# R7FA8D1BH register map
Vendor: Renesas; Series: RA8; File version: 1.2
CPU: CM85 r0p0, little endian, MPU, FPU, VTOR, 4 interrupt priority bits
Registers are 32-bit, read-write, reset 0x0 unless marked. A register's access mark holds for its fields unless they carry their own. Offsets are from the block's base; [hi:lo] are bit positions; 'fields as' and 'values as' point back to an identical list.

## SSIE0 — Serial Sound Interface Enhanced (SSIE)
Base 0x4025D000
Same registers: SSIE1 0x4025D100, SSIE0_NS 0x5025D000, SSIE1_NS 0x5025D100
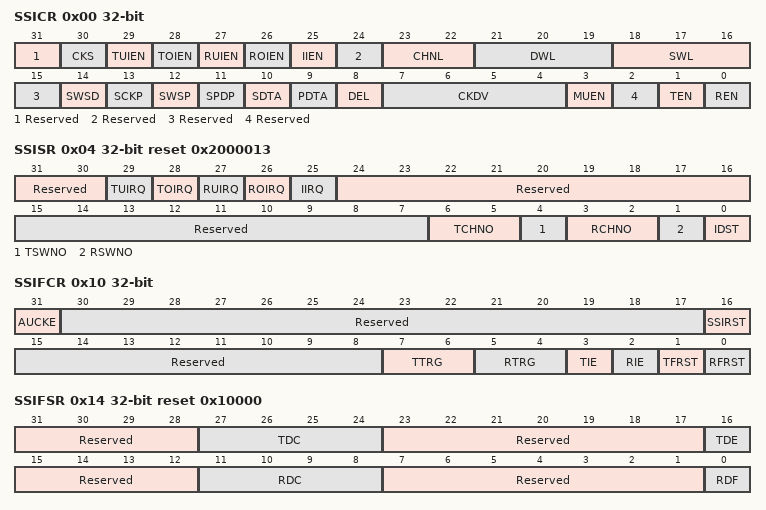
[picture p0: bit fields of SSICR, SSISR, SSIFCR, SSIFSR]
0x00 SSICR — Control Register
  [31] Reserved — This bit is read as 0. The write value should be 0.
  [30] CKS — Oversampling Clock Select
    0=AUDIO_CLK input; 1=Setting prohibited
  [29] TUIEN — Transmit Underflow Interrupt Enable
    0=Disables an underflow interrupt; 1=Enables an underflow interrupt
  [28] TOIEN — Transmit Overflow Interrupt Enable
    0=Disables an overflow interrupt; 1=Enables an overflow interrupt
  [27] RUIEN — Receive Underflow Interrupt Enable
    values as TUIEN
  [26] ROIEN — Receive Overflow Interrupt Enable
    values as TOIEN
  [25] IIEN — Idle Mode Interrupt Enable
    0=Disables an idle mode interrupt; 1=Enables an idle mode interrupt
  [24] Reserved — This bit is read as 0. The write value should be 0.
  [23:22] CHNL — Channels
    0=One channel; other=others (Settings other than above are prohibited.)
  [21:19] DWL — Data Word Length
    0=8 bits; 1=16 bits; 2=18 bits; 3=20 bits; 4=22 bits; 5=24 bits; other=others (Settings other than above are prohibited.)
  [18:16] SWL — System Word LengthSet the system word length to the bit clock frequency/2 fs.
    0=8 bits (serial bit clock frequency = 16fs ); 1=16 bits (serial bit clock frequency = 32fs ); 2=24 bits (serial bit clock frequency = 48fs ); 3=32 bits (serial bit clock frequency = 64fs ); other=others (Settings other than above are prohibited.)
  [15] Reserved — This bit is read as 0. The write value should be 0.
  [14] SWSD — Serial WS Direction NOTE: Only the following settings are allowed: (SCKD, SWSD) = (0, 0) and (1, 1). Other settings are prohibited.
    0=Serial word select is input, slave mode; 1=Serial word select is output, master mode
  [13] SCKP — Serial Bit Clock Polarity
    0=SSIWS and SSIDATA change at the SSISCK falling edge (sampled at the SCK rising edge); 1=SSIWS and SSIDATA change at the SSISCK rising edge (sampled at the SCK falling edge)
  [12] SWSP — Serial WS Polarity
    0=SSIWS is low for 1st channel, high for 2nd channel; 1=SSIWS is high for 1st channel, low for 2nd channel
  [11] SPDP — Serial Padding Polarity
    0=Padding bits are low; 1=Padding bits are high
  [10] SDTA — Serial Data Alignment
    0=Transmitting and receiving in the order of serial data and padding bits; 1=Transmitting and receiving in the order of padding bits and serial data
  [9] PDTA — Parallel Data Alignment
    0=The lower bits of parallel data (SSITDR, SSIRDR) are transferred prior to the upper bits.(When data word length is 8 or 16 bits) / Parallel data (SSITDR, SSIRDR) is left-aligned.(When data word length is 18, 20, 22, or 24 bits); 1=The upper bits of parallel data (SSITDR, SSIRDR) are transferred prior to the lower bits.(When data word length is 8 or 16 bits) / Parallel data (SSITDR, SSIRDR) is right-aligned.(When data word length is 18, 20, 22, or 24 bits)
  [8] DEL — Serial Data Delay
    0=1 clock cycle delay between SSIWS and SSIDATA; 1=No delay between SSIWS and SSIDATA
  [7:4] CKDV — Serial Oversampling Clock Division Ratio
    0=CLK; 1=CLK/2; 2=CLK/4; 3=CLK/8; 4=CLK/16; 5=CLK/32; 6=CLK/64; 7=CLK/128; 8=CLK/6; 9=CLK/12 (These bits are only settable for channel 0. Setting these bits in the register for channel 1 is prohibited.); 10=CLK/24; 11=CLK/48(These bits are only settable for channel 0. Setting these bits in the register for channel 1 is prohibited.); 12=CLK/96(These bits are only settable for channel 0. Setting these bits in the register for channel 1 is prohibited.); other=others (Settings other than above are prohibited.)
  [3] MUEN — Mute EnableNOTE: When this module is muted, the value of outputting serial data is rewritten to 0 but data transmission is not stopped. Write dummy data to the SSIFTDR not to generate a transmit underflow because the number of data in the transmit FIFO is decreasing.
    0=This module is not muted; 1=This module is muted
  [2] Reserved — This bit is read as 0. The write value should be 0.
  [1] TEN — Transmit Enable
    0=Disables the transmit operation; 1=Enables the transmit operation
  [0] REN — Receive Enable
    0=Disables the receive operation; 1=Enables the receive operation
0x04 SSISR reset 0x2000013 (reset mask 0x3E00007F) — Status Register
  [31:30] Reserved — These bits are read as 00. The write value should be 00.
  [29] TUIRQ write-0-clears read-modifies — Transmit Underflow Error Interrupt Status Flag NOTE: Writable only to clear the flag. Confirm the value is 1 and then write 0.
    0=No transmit underflow has occurred; 1=A transmit underflow has occurred
  [28] TOIRQ write-0-clears read-modifies — Transmit Overflow Error Interrupt Status Flag NOTE: Writable only to clear the flag. Confirm the value is 1 and then write 0.
    0=No transmit overflow has occurred; 1=A transmit overflow has occurred
  [27] RUIRQ write-0-clears read-modifies — Receive Underflow Error Interrupt Status Flag NOTE: Writable only to clear the flag. Confirm the value is 1 and then write 0.
    0=No receive underflow has occurred; 1=A receive underflow has occurred
  [26] ROIRQ write-0-clears read-modifies — Receive Overflow Error Interrupt Status Flag NOTE: Writable only to clear the flag. Confirm the value is 1 and then write 0.
    0=No receive overflow has occurred; 1=A receive overflow has occurred
  [25] IIRQ ro — Idle Mode Interrupt Status Flag
    0=This module is not in idle state; 1=This module is in idle state
  [24:16] Reserved — These bits are read as 000000000. The write value should be 000000000.
  [15:7] Reserved — These bits are read as 000000000. The write value should be 000000000.
  [6:5] TCHNO ro — Transmit Channel Number
  [4] TSWNO ro — Transmit Serial Word Number
  [3:2] RCHNO ro — Receive Channel Number.These bits are read as 00b.
  [1] RSWNO ro — Receive Serial Word Number
  [0] IDST ro — Idle Mode Status Flag
    0=Serial bus is operating; 1=The current communication is stopped
0x10 SSIFCR — FIFO Control Register
  [31] AUCKE — Oversampling Clock Enable
    0=The oversampling clock is disabled; 1=The oversampling clock is enabled
  [30:17] Reserved — These bits are read as 00000000000000. The write value should be 00000000000000.
  [16] SSIRST — SSI soft ware reset
    0=Clears the SSI software reset; 1=initiates the SSI software reset
  [15:8] Reserved — These bits are read as 00000000. The write value should be 00000000.
  [7:6] TTRG — Transmit Data Trigger Number NOTE: The values in parenthesis are the number of empty stages in SSIFTDR at which the TDE flag is set.
    0=7 (1); 1=6 (2); 2=4 (4); 3=2 (6)
  [5:4] RTRG — Receive Data Trigger Number
    0=1; 1=2; 2=4; 3=6
  [3] TIE — Transmit Interrupt Enable NOTE: TXI can be cleared by clearing either the TDE flag (see the description of the TDE bit for details) or TIE bit.
    0=Transmit data empty interrupt (TXI) request is disabled; 1=Transmit data empty interrupt (TXI) request is enabled
  [2] RIE — Receive Interrupt Enable NOTE: RXI can be cleared by clearing either the RDF flag (see the description of the RDF bit for details) or RIE bit.
    0=Receive data full interrupt (RXI) request is disabled; 1=Receive data full interrupt (RXI) request is enabled
  [1] TFRST — Transmit FIFO Data Register Reset
    0=Clears the transmit data FIFO reset; 1=Initiates the transmit data FIFO reset
  [0] RFRST — Receive FIFO Data Register Reset
    0=Clears the receive data FIFO reset; 1=Initiates the receive data FIFO reset
0x14 SSIFSR reset 0x10000 — FIFO Status Register
  [31:28] Reserved — These bits are read as 0000. The write value should be 0000.
  [27:24] TDC ro — Transmit Data Indicate Flag(Indicates the number of data units stored in SSIFTDR)
  [23:17] Reserved — These bits are read as 0000000. The write value should be 0000000.
  [16] TDE write-0-clears read-modifies — Transmit Data Empty Flag NOTE: Since the SSIFTDR register is a 32-byte FIFO register, the maximum number of bytes that can be written to it while the TDE flag is 1 is 8 - TDC[3:0]. If writing data to the SSIFTDR register is continued after all the data is written, writing will be invalid and an overflow occurs.
    0=Number of data bytes for transmission in SSIFTDR is greater than the set transmit trigger number; 1=Number of data bytes for transmission in SSIFTDR is equal to or less than the set transmit trigger number
  [15:12] Reserved — These bits are read as 0000. The write value should be 0000.
  [11:8] RDC ro — Receive Data Indicate Flag(Indicates the number of data units stored in SSIFRDR)
  [7:1] Reserved — These bits are read as 0000000. The write value should be 0000000.
  [0] RDF write-0-clears read-modifies — Receive Data Full Flag NOTE: Since the SSIFRDR register is a 32-byte FIFO register, the maximum number of data bytes that can be read from it while the RDF flag is 1 is indicated in the RDC[3:0] flags. If reading data from the SSIFRDR register is continued after all the data is read, undefined values will be read.
    0=Number of received data bytes in SSIFRDR is less than the set receive trigger number; 1=Number of received data bytes in SSIFRDR is equal to or greater than the set receive trigger number
0x18 SSIFTDR wo reset not defined — Transmit FIFO Data Register
  [31:0] SSIFTDR — SSIFTDR is a write-only FIFO register consisting of eight stages of 32-bit registers for storing data to be serially transmitted. NOTE: that when the SSIFTDR register is full of data (32 bytes), the next data cannot be written to it. If writing is attempted, it will be ignored and an overflow occurs.
0x1C SSIFRDR ro reset not defined — Receive FIFO Data Register
  [31:0] SSIFRDR — SSIFRDR is a read-only FIFO register consisting of eight stages of 32-bit registers for storing serially received data.
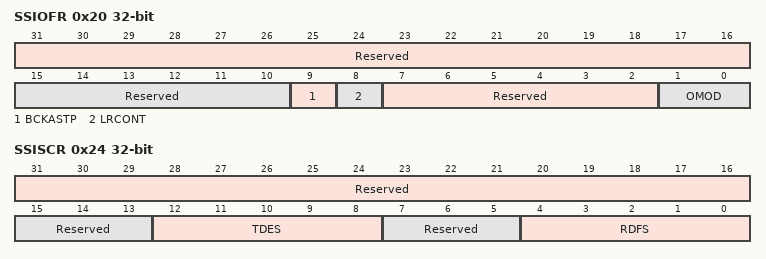
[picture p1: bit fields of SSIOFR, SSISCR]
0x20 SSIOFR — Audio Format Register
  [31:16] Reserved — These bits are read as 0000000000000000. The write value should be 0000000000000000.
  [15:10] Reserved — These bits are read as 000000. The write value should be 000000.
  [9] BCKASTP — Whether to Enable Stopping BCK Output When SSIE is in Idle Status
    0=Always outputs BCK to the SSIBCK pin; 1=Automatically controls output of BCK to the SSIBCK pin
  [8] LRCONT — Whether to Enable LRCK/FS Continuation
    0=Disables LRCK/FS continuation; 1=Enables LRCK/FS continuation
  [7:2] Reserved — These bits are read as 000000. The write value should be 000000.
  [1:0] OMOD — Audio Format Select
    0=I2S format; 1=TDM format; 2=Monaural format; 3=Setting prohibited
0x24 SSISCR — Status Control Register
  [31:16] Reserved — These bits are read as 0000000000000000. The write value should be 0000000000000000.
  [15:13] Reserved — These bits are read as 000. The write value should be 000.
  [12:8] TDES — TDE Setting Condition Select
    0=SSIFTDR has one stage or more free space; 1=SSIFTDR has two stages or more free space (snip); 30=SSIFTDR has thirty-one stages or more free space; 31=SSIFTDR has thirty-two stages or more free space
  [7:5] Reserved — These bits are read as 000. The write value should be 000.
  [4:0] RDFS — RDF Setting Condition Select
    0=SSIFRDR has one stage or more data size; 1=SSIFRDR has two stages or more data size (snip); 30=SSIFRDR has thirty-one stages or more data size; 31=SSIFRDR has thirty-two stages or more data size
